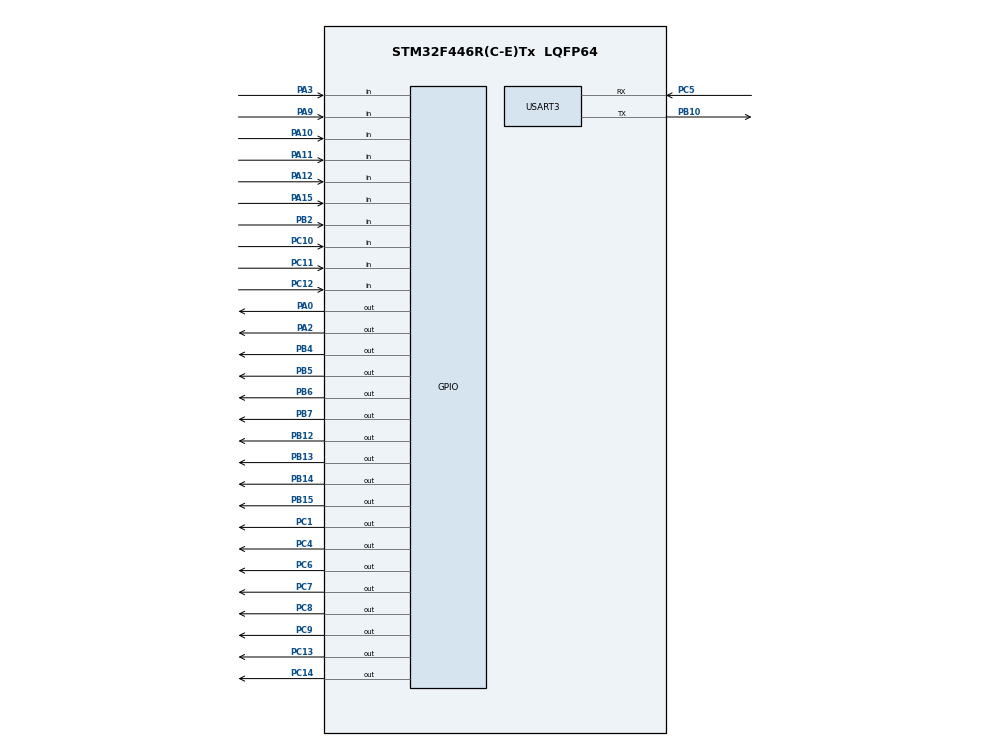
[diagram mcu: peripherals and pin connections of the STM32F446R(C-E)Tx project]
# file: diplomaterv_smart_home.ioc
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FREERTOS.Queues01=CommandQueue,20,char*,0,Dynamic,NULL,NULL;StatusQueue,20,char*,0,Dynamic,NULL,NULL
FREERTOS.Tasks01=defaultTask,0,128,StartDefaultTask,Default,NULL,Dynamic,NULL,NULL;CommunicationTa,0,128,StartTaskCommunication,Default,NULL,Dynamic,NULL,NULL;SupverVisiorTas,-3,128,StartTaskSuperVisior,Default,NULL,Dynamic,NULL,NULL
Mcu.Family=STM32F4
Mcu.Name=STM32F446R(C-E)Tx
Mcu.Package=LQFP64
NVIC.PriorityGroup=NVIC_PRIORITYGROUP_4
NVIC.TIM1_UP_TIM10_IRQn=true\:0\:0\:false\:false\:true\:false\:false\:true
NVIC.TimeBase=TIM1_UP_TIM10_IRQn
NVIC.TimeBaseIP=TIM1
PA0-WKUP.Signal=GPIO_Output
PA10.Signal=GPIO_Input
PA11.Signal=GPIO_Input
PA12.Signal=GPIO_Input
PA13.Mode=Serial_Wire
PA13.Signal=SYS_JTMS-SWDIO
PA14.Mode=Serial_Wire
PA14.Signal=SYS_JTCK-SWCLK
PA15.Signal=GPIO_Input
PA2.Signal=GPIO_Output
PA3.Signal=GPIO_Input
PA4.Signal=SPI1_NSS
PA5.Signal=SPI1_SCK
PA6.Signal=SPI1_MISO
PA7.Signal=SPI1_MOSI
PA9.Signal=GPIO_Input
PB10.Mode=Asynchronous
PB10.Signal=USART3_TX
PB12.Signal=GPIO_Output
PB13.Signal=GPIO_Output
PB14.Signal=GPIO_Output
PB15.Signal=GPIO_Output
PB2.Signal=GPIO_Input
PB3.Signal=SYS_JTDO-SWO
PB4.Signal=GPIO_Output
PB5.Signal=GPIO_Output
PB6.Signal=GPIO_Output
PB7.Signal=GPIO_Output
PB8.Signal=I2C1_SCL
PB9.Signal=I2C1_SDA
PC1.Signal=GPIO_Output
PC10.Signal=GPIO_Input
PC11.Signal=GPIO_Input
PC12.Signal=GPIO_Input
PC13.Signal=GPIO_Output
PC14-OSC32_IN.Signal=GPIO_Output
PC4.Signal=GPIO_Output
PC5.Mode=Asynchronous
PC5.Signal=USART3_RX
PC6.Signal=GPIO_Output
PC7.Signal=GPIO_Output
PC8.Signal=GPIO_Output
PC9.Signal=GPIO_Output
PH0-OSC_IN.Signal=RCC_OSC_IN
PH1-OSC_OUT.Signal=RCC_OSC_OUT
ProjectManager.HeapSize=0x200
ProjectManager.StackSize=0x400
ProjectManager.TargetToolchain=STM32CubeIDE
RCC.CortexFreq_Value=16000000
RCC.USBFreq_Value=96000000
RCC.VCOOutputFreq_Value=192000000
USART3.VirtualMode=VM_ASYNC
VP_FREERTOS_VS_CMSIS_V1.Mode=CMSIS_V1
VP_RTC_VS_RTC_Activate.Mode=RTC_Enabled
VP_RTC_VS_RTC_Calendar.Mode=RTC_Calendar
VP_SYS_VS_tim1.Mode=TIM1
board=custom

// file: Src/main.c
/* USER CODE BEGIN Header */
/**
  ******************************************************************************
  * @file           : main.c
  * @brief          : Main program body
  ******************************************************************************
  * @attention
  *
  * <h2><center>&copy; Copyright (c) 2019 STMicroelectronics.
  * All rights reserved.</center></h2>
  *
  * This software component is licensed by ST under BSD 3-Clause license,
  * the "License"; You may not use this file except in compliance with the
  * License. You may obtain a copy of the License at:
  *                        opensource.org/licenses/BSD-3-Clause
  *
  ******************************************************************************
  */
/* USER CODE END Header */

#include "main.h"
#include "cmsis_os.h"

RTC_HandleTypeDef hrtc;

UART_HandleTypeDef huart3;

osThreadId defaultTaskHandle;
osThreadId CommunicationTaHandle;
osThreadId SupverVisiorTasHandle;
osMessageQId CommandQueueHandle;
osMessageQId StatusQueueHandle;

void SystemClock_Config(void);
static void MX_GPIO_Init(void);
static void MX_RTC_Init(void);
static void MX_USART3_UART_Init(void);
void StartDefaultTask(void const * argument);
void StartTaskCommunication(void const * argument);
void StartTaskSuperVisior(void const * argument);

int main(void)
{

  /* MCU Configuration--------------------------------------------------------*/

  /* Reset of all peripherals, Initializes the Flash interface and the Systick. */
  HAL_Init();

  /* Configure the system clock */
  SystemClock_Config();

  /* Initialize all configured peripherals */
  MX_GPIO_Init();
  MX_RTC_Init();
  MX_USART3_UART_Init();

  /* Create the queue(s) */
  /* definition and creation of CommandQueue */
  osMessageQDef(CommandQueue, 20, char*);
  CommandQueueHandle = osMessageCreate(osMessageQ(CommandQueue), NULL);

  /* definition and creation of StatusQueue */
  osMessageQDef(StatusQueue, 20, char*);
  StatusQueueHandle = osMessageCreate(osMessageQ(StatusQueue), NULL);

  /* Create the thread(s) */
  /* definition and creation of defaultTask */
  osThreadDef(defaultTask, StartDefaultTask, osPriorityNormal, 0, 128);
  defaultTaskHandle = osThreadCreate(osThread(defaultTask), NULL);

  /* definition and creation of CommunicationTa */
  osThreadDef(CommunicationTa, StartTaskCommunication, osPriorityNormal, 0, 128);
  CommunicationTaHandle = osThreadCreate(osThread(CommunicationTa), NULL);

  /* definition and creation of SupverVisiorTas */
  osThreadDef(SupverVisiorTas, StartTaskSuperVisior, osPriorityIdle, 0, 128);
  SupverVisiorTasHandle = osThreadCreate(osThread(SupverVisiorTas), NULL);

  /* Start scheduler */
  osKernelStart();

  /* We should never get here as control is now taken by the scheduler */

  /* Infinite loop */
  while (1)
  {

  }
}

void SystemClock_Config(void)
{
  RCC_OscInitTypeDef RCC_OscInitStruct = {0};
  RCC_ClkInitTypeDef RCC_ClkInitStruct = {0};
  RCC_PeriphCLKInitTypeDef PeriphClkInitStruct = {0};

  /** Configure the main internal regulator output voltage
  */
  __HAL_RCC_PWR_CLK_ENABLE();
  __HAL_PWR_VOLTAGESCALING_CONFIG(PWR_REGULATOR_VOLTAGE_SCALE3);
  /** Initializes the CPU, AHB and APB busses clocks
  */
  RCC_OscInitStruct.OscillatorType = RCC_OSCILLATORTYPE_HSI|RCC_OSCILLATORTYPE_LSI;
  RCC_OscInitStruct.LSEState = RCC_LSE_OFF;
  RCC_OscInitStruct.HSIState = RCC_HSI_ON;
  RCC_OscInitStruct.HSICalibrationValue = RCC_HSICALIBRATION_DEFAULT;
  RCC_OscInitStruct.LSIState = RCC_LSI_ON;
  RCC_OscInitStruct.PLL.PLLState = RCC_PLL_NONE;
  if (HAL_RCC_OscConfig(&RCC_OscInitStruct) != HAL_OK)
  {
    Error_Handler();
  }
  /** Initializes the CPU, AHB and APB busses clocks
  */
  RCC_ClkInitStruct.ClockType = RCC_CLOCKTYPE_HCLK|RCC_CLOCKTYPE_SYSCLK
                              |RCC_CLOCKTYPE_PCLK1|RCC_CLOCKTYPE_PCLK2;
  RCC_ClkInitStruct.SYSCLKSource = RCC_SYSCLKSOURCE_HSI;
  RCC_ClkInitStruct.AHBCLKDivider = RCC_SYSCLK_DIV1;
  RCC_ClkInitStruct.APB1CLKDivider = RCC_HCLK_DIV1;
  RCC_ClkInitStruct.APB2CLKDivider = RCC_HCLK_DIV1;

  if (HAL_RCC_ClockConfig(&RCC_ClkInitStruct, FLASH_LATENCY_0) != HAL_OK)
  {
    Error_Handler();
  }
  PeriphClkInitStruct.PeriphClockSelection = RCC_PERIPHCLK_RTC;
  PeriphClkInitStruct.RTCClockSelection = RCC_RTCCLKSOURCE_LSI;
  if (HAL_RCCEx_PeriphCLKConfig(&PeriphClkInitStruct) != HAL_OK)
  {
    Error_Handler();
  }
}

static void MX_RTC_Init(void)
{

  RTC_TimeTypeDef sTime = {0};
  RTC_DateTypeDef sDate = {0};

  /** Initialize RTC Only
  */
  hrtc.Instance = RTC;
  hrtc.Init.HourFormat = RTC_HOURFORMAT_24;
  hrtc.Init.AsynchPrediv = 127;
  hrtc.Init.SynchPrediv = 255;
  hrtc.Init.OutPut = RTC_OUTPUT_DISABLE;
  hrtc.Init.OutPutPolarity = RTC_OUTPUT_POLARITY_HIGH;
  hrtc.Init.OutPutType = RTC_OUTPUT_TYPE_OPENDRAIN;
  if (HAL_RTC_Init(&hrtc) != HAL_OK)
  {
    Error_Handler();
  }

  /** Initialize RTC and set the Time and Date
  */
  sTime.Hours = 0x0;
  sTime.Minutes = 0x0;
  sTime.Seconds = 0x0;
  sTime.DayLightSaving = RTC_DAYLIGHTSAVING_NONE;
  sTime.StoreOperation = RTC_STOREOPERATION_RESET;
  if (HAL_RTC_SetTime(&hrtc, &sTime, RTC_FORMAT_BCD) != HAL_OK)
  {
    Error_Handler();
  }
  sDate.WeekDay = RTC_WEEKDAY_MONDAY;
  sDate.Month = RTC_MONTH_JANUARY;
  sDate.Date = 0x1;
  sDate.Year = 0x0;

  if (HAL_RTC_SetDate(&hrtc, &sDate, RTC_FORMAT_BCD) != HAL_OK)
  {
    Error_Handler();
  }

}

static void MX_USART3_UART_Init(void)
{

  huart3.Instance = USART3;
  huart3.Init.BaudRate = 115200;
  huart3.Init.WordLength = UART_WORDLENGTH_8B;
  huart3.Init.StopBits = UART_STOPBITS_1;
  huart3.Init.Parity = UART_PARITY_NONE;
  huart3.Init.Mode = UART_MODE_TX_RX;
  huart3.Init.HwFlowCtl = UART_HWCONTROL_NONE;
  huart3.Init.OverSampling = UART_OVERSAMPLING_16;
  if (HAL_UART_Init(&huart3) != HAL_OK)
  {
    Error_Handler();
  }

}

static void MX_GPIO_Init(void)
{
  GPIO_InitTypeDef GPIO_InitStruct = {0};

  /* GPIO Ports Clock Enable */
  __HAL_RCC_GPIOC_CLK_ENABLE();
  __HAL_RCC_GPIOH_CLK_ENABLE();
  __HAL_RCC_GPIOA_CLK_ENABLE();
  __HAL_RCC_GPIOB_CLK_ENABLE();

  /*Configure GPIO pin Output Level */
  HAL_GPIO_WritePin(GPIOC, GPIO_PIN_13|GPIO_PIN_14|GPIO_PIN_1|GPIO_PIN_4
                          |GPIO_PIN_6|GPIO_PIN_7|GPIO_PIN_8|GPIO_PIN_9, GPIO_PIN_RESET);

  /*Configure GPIO pin Output Level */
  HAL_GPIO_WritePin(GPIOA, GPIO_PIN_0|GPIO_PIN_2, GPIO_PIN_RESET);

  /*Configure GPIO pin Output Level */
  HAL_GPIO_WritePin(GPIOB, GPIO_PIN_12|GPIO_PIN_13|GPIO_PIN_14|GPIO_PIN_15
                          |GPIO_PIN_4|GPIO_PIN_5|GPIO_PIN_6|GPIO_PIN_7, GPIO_PIN_RESET);

  /*Configure GPIO pins : PC13 PC14 PC1 PC4
                           PC6 PC7 PC8 PC9 */
  GPIO_InitStruct.Pin = GPIO_PIN_13|GPIO_PIN_14|GPIO_PIN_1|GPIO_PIN_4
                          |GPIO_PIN_6|GPIO_PIN_7|GPIO_PIN_8|GPIO_PIN_9;
  GPIO_InitStruct.Mode = GPIO_MODE_OUTPUT_PP;
  GPIO_InitStruct.Pull = GPIO_NOPULL;
  GPIO_InitStruct.Speed = GPIO_SPEED_FREQ_LOW;
  HAL_GPIO_Init(GPIOC, &GPIO_InitStruct);

  /*Configure GPIO pins : PA0 PA2 */
  GPIO_InitStruct.Pin = GPIO_PIN_0|GPIO_PIN_2;
  GPIO_InitStruct.Mode = GPIO_MODE_OUTPUT_PP;
  GPIO_InitStruct.Pull = GPIO_NOPULL;
  GPIO_InitStruct.Speed = GPIO_SPEED_FREQ_LOW;
  HAL_GPIO_Init(GPIOA, &GPIO_InitStruct);

  /*Configure GPIO pins : PA3 PA9 PA10 PA11
                           PA12 PA15 */
  GPIO_InitStruct.Pin = GPIO_PIN_3|GPIO_PIN_9|GPIO_PIN_10|GPIO_PIN_11
                          |GPIO_PIN_12|GPIO_PIN_15;
  GPIO_InitStruct.Mode = GPIO_MODE_INPUT;
  GPIO_InitStruct.Pull = GPIO_NOPULL;
  HAL_GPIO_Init(GPIOA, &GPIO_InitStruct);

  /*Configure GPIO pins : PA4 PA5 PA6 PA7 */
  GPIO_InitStruct.Pin = GPIO_PIN_4|GPIO_PIN_5|GPIO_PIN_6|GPIO_PIN_7;
  GPIO_InitStruct.Mode = GPIO_MODE_AF_PP;
  GPIO_InitStruct.Pull = GPIO_NOPULL;
  GPIO_InitStruct.Speed = GPIO_SPEED_FREQ_VERY_HIGH;
  GPIO_InitStruct.Alternate = GPIO_AF5_SPI1;
  HAL_GPIO_Init(GPIOA, &GPIO_InitStruct);

  /*Configure GPIO pin : PB2 */
  GPIO_InitStruct.Pin = GPIO_PIN_2;
  GPIO_InitStruct.Mode = GPIO_MODE_INPUT;
  GPIO_InitStruct.Pull = GPIO_NOPULL;
  HAL_GPIO_Init(GPIOB, &GPIO_InitStruct);

  /*Configure GPIO pins : PB12 PB13 PB14 PB15
                           PB4 PB5 PB6 PB7 */
  GPIO_InitStruct.Pin = GPIO_PIN_12|GPIO_PIN_13|GPIO_PIN_14|GPIO_PIN_15
                          |GPIO_PIN_4|GPIO_PIN_5|GPIO_PIN_6|GPIO_PIN_7;
  GPIO_InitStruct.Mode = GPIO_MODE_OUTPUT_PP;
  GPIO_InitStruct.Pull = GPIO_NOPULL;
  GPIO_InitStruct.Speed = GPIO_SPEED_FREQ_LOW;
  HAL_GPIO_Init(GPIOB, &GPIO_InitStruct);

  /*Configure GPIO pins : PC10 PC11 PC12 */
  GPIO_InitStruct.Pin = GPIO_PIN_10|GPIO_PIN_11|GPIO_PIN_12;
  GPIO_InitStruct.Mode = GPIO_MODE_INPUT;
  GPIO_InitStruct.Pull = GPIO_NOPULL;
  HAL_GPIO_Init(GPIOC, &GPIO_InitStruct);

  /*Configure GPIO pins : PB8 PB9 */
  GPIO_InitStruct.Pin = GPIO_PIN_8|GPIO_PIN_9;
  GPIO_InitStruct.Mode = GPIO_MODE_AF_OD;
  GPIO_InitStruct.Pull = GPIO_PULLUP;
  GPIO_InitStruct.Speed = GPIO_SPEED_FREQ_VERY_HIGH;
  GPIO_InitStruct.Alternate = GPIO_AF4_I2C1;
  HAL_GPIO_Init(GPIOB, &GPIO_InitStruct);

}

void StartDefaultTask(void const * argument)
{

  for(;;)
  {
    osDelay(1);
  }
}

void StartTaskCommunication(void const * argument)
{
  /* USER CODE BEGIN StartTaskCommunication */
  /* Infinite loop */
  for(;;)
  {

	  osDelay(1);
	  HAL_GPIO_TogglePin(GPIOC,GPIO_PIN_9);
	  //HAL_GPIO_TogglePin(GPIOC,GPIO_PIN_8);
	  osDelay(1000);
  }
  /* USER CODE END StartTaskCommunication */
}

void StartTaskSuperVisior(void const * argument)
{
  for(;;)
  {
    osDelay(1);
  }
}

void HAL_TIM_PeriodElapsedCallback(TIM_HandleTypeDef *htim)
{
  if (htim->Instance == TIM1) {
    HAL_IncTick();
  }
}

void Error_Handler(void)
{
}

/************************ (C) COPYRIGHT STMicroelectronics *****END OF FILE****/
